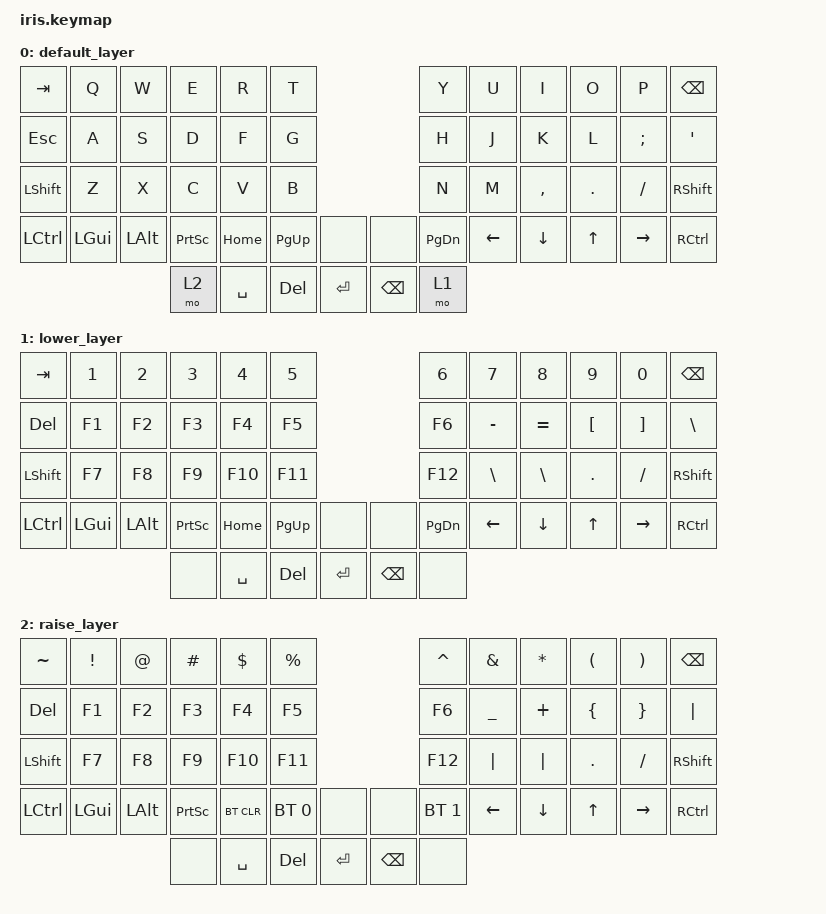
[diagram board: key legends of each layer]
/*
 * Copyright (c) 2020 The ZMK Contributors
 *
 * SPDX-License-Identifier: MIT
 */

#include <behaviors.dtsi>
#include <dt-bindings/zmk/keys.h>
#include <dt-bindings/zmk/bt.h>

/ {
	keymap {
		compatible = "zmk,keymap";

		default_layer {
// ------------------------------------------------------------------------------------------------------------
// |  TAB     |  Q     |  W     |  E   |  R     |  T   |                            |  Y       |  U     |  I      |  O    |   P     | BSPC  |
// |  ESC     |  A     |  S     |  D   |  F     |  G   |                            |  H       |  J     |  K      |  L    |   ;     |   '   |
// | SHIFT    |  Z     |  X     |  C   |  V     |  B   |                            |  N       |  M     |  ,      |  .    |   /     | SHIFT |
// | CNTRL    | GUI    | ALT    | PSCRN|  HOME  | PG_UP   |  NONE  |      |  NONE   | PG_DN    |  <     |  v      |  ^    |   >     | CNTRL |
//                     	               | RAISE  | SPACE   |  DEL   |      | ENTER   | BSPC     |  LOWER |
			bindings = <
    &kp TAB   &kp Q    &kp W    &kp E  &kp R    &kp T                               &kp Y      &kp U    &kp I     &kp O   &kp P     &kp BSPC
    &kp ESC   &kp A    &kp S    &kp D  &kp F    &kp G                               &kp H      &kp J    &kp K     &kp L   &kp SEMI  &kp SQT
    &kp LSHFT &kp Z    &kp X    &kp C  &kp V    &kp B                               &kp N      &kp M    &kp COMMA &kp DOT &kp FSLH  &kp RSHFT
    &kp LCTRL &kp LGUI &kp LALT &kp PSCRN  &kp HOME &kp PG_UP &none       &none     &kp PG_DN &kp LEFT  &kp DOWN  &kp UP  &kp RIGHT &kp RCTRL
                   		       &mo 2    &kp SPACE &kp DEL         &kp RET   &kp BSPC   &mo 1
			>;
		};

		lower_layer {
// ------------------------------------------------------------------------------------------------------------
// |    `     |   1    |  2     |  3   |  4     |  5   |                            |  6       |  7     |  8      |  9    |   0     | BSPC  |
// |  DEL     |  F1    |  F2    |  F3  |  F4    |  F5  |                            |  F6      |  -     |  =      |  [    |   ]     |   \   |
// | SHIFT    |  F7    |  F8    |  F9  |  F10   |  F11 |                            |  F12     |  \     |  \      |  .    |   /     | SHIFT |
// | CNTRL    | GUI    | ALT    | PSCRN|  HOME  | PG_UP   |  NONE  |      | NONE    | PG_DN    |  <     |  v      |  ^    |   >     | CNTRL |
//                     	               | NONE   | SPACE   |  DEL   |      | ENTER   | BSPC     |  NONE  |
			bindings = <
    &kp TAB   &kp N1   &kp N2   &kp N3 &kp N4   &kp N5                              &kp N6     &kp N7   &kp N8    &kp N9  &kp N0    &kp BSPC
    &kp DEL   &kp F1   &kp F2   &kp F3 &kp F4   &kp F5                              &kp F6     &kp MINUS&kp EQUAL &kp LBKT&kp RBKT  &kp BSLH
    &kp LSHFT &kp F7   &kp F8   &kp F9 &kp F10  &kp F11                             &kp F12    &kp BSLH &kp BSLH  &kp DOT &kp FSLH  &kp RSHFT
    &kp LCTRL &kp LGUI &kp LALT &kp PSCRN  &kp HOME &kp PG_UP &none       &none     &kp PG_DN &kp LEFT  &kp DOWN  &kp UP  &kp RIGHT &kp RCTRL
                   		       &none    &kp SPACE &kp DEL         &kp RET   &kp BSPC   &none
			>;
		};

		raise_layer {
// ------------------------------------------------------------------------------------------------------------
// |  ~       |  !     |  @     |  #   |  $     |  %   |                            |  ^       |  &     |  *      |  (    |   )     | BSPC  |
// |  DEL     |  F1    |  F2    |  F3  |  F4    |  F5  |                            |  F6      |  _     |  +      |  {    |   }     |   |   |
// | SHIFT    |  F7    |  F8    |  F9  |  F10   |  F11 |                            |  F12     |  |     |  |      |  .    |   /     | SHIFT |
// | CNTRL    | GUI    | ALT    | PSCRN|  BTCLR | BT 0    |  NONE  |      |  NONE   | BT 1     |  <     |  v      |  ^    |   >     | CNTRL |
//                     	               | NONE   | SPACE   |  DEL   |      | ENTER   | BSPC     |  NONE  |
			bindings = <
    &kp TILDE &kp EXCL &kp AT   &kp HASH&kp DLLR &kp PRCNT                           &kp CARET  &kp AMPS &kp STAR  &kp LPAR&kp RPAR  &kp BSPC
    &kp DEL   &kp F1   &kp F2   &kp F3 &kp F4   &kp F5                              &kp F6     &kp UNDER&kp PLUS  &kp LBRC&kp RBRC  &kp PIPE
    &kp LSHFT &kp F7   &kp F8   &kp F9 &kp F10  &kp F11                             &kp F12    &kp PIPE &kp PIPE  &kp DOT &kp FSLH  &kp RSHFT
    &kp LCTRL &kp LGUI &kp LALT &kp PSCRN  &bt BT_CLR &bt BT_SEL 0 &none  &none     &bt BT_SEL 1 &kp LEFT  &kp DOWN  &kp UP  &kp RIGHT &kp RCTRL
                   		       &none    &kp SPACE &kp DEL         &kp RET   &kp BSPC   &none
			>;
		};
	};
};
